# NAVSS0_UDMASS_INTA_0_UDMASS_INTA0_CFG_GCNTCFG register map
Vendor: Texas Instruments
Peripheral module from a debugger description file (folder J721S2).
Registers are 64-bit, read-write, reset 0xFFFF unless marked. A register's access mark holds for its fields unless they carry their own. Offsets are as the file gives them; lines under a group give offsets from that group; [hi:lo] are bit positions; {n}, {i} and the like mark numbered series; 'fields as' and 'values as' point back to an identical list; <NAME> marks a mode.

## NAVSS0_UDMASS_INTA_0_UDMASS_INTA0_CFG_GCNTCFG
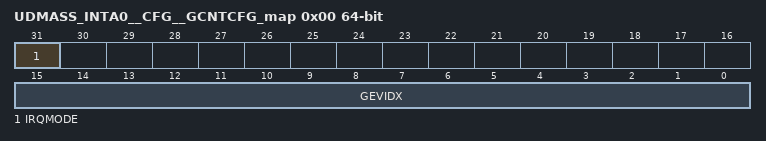
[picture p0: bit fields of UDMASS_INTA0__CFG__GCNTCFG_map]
0x00 UDMASS_INTA0__CFG__GCNTCFG_map — The Global Event Mapping register controls the egress global event index for this event count. This register may also be optionally used to directly set an interrupt status bit by using the irqmode flag.
  [31] IRQMODE — IRQ Mode Flag. When set, this register act like a mapper with bitnum in 5:0 and regnum in 14:6.
  [15:0] GEVIDX — Global event index. This field specifies the index of the outgoing global event. Set to 0xFFFF to disable.
